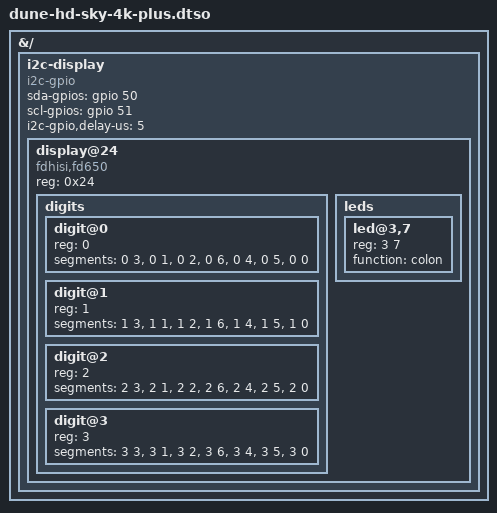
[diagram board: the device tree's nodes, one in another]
/dts-v1/;
/plugin/;

#include <dt-bindings/gpio/gpio.h>
#include <dt-bindings/leds/common.h>

&{/} {

	i2c-display {
		compatible = "i2c-gpio";
		sda-gpios = <&gpio 50 (GPIO_ACTIVE_HIGH | GPIO_OPEN_DRAIN)>;
		scl-gpios = <&gpio 51 (GPIO_ACTIVE_HIGH | GPIO_OPEN_DRAIN)>;
		i2c-gpio,delay-us = <5>;
		#address-cells = <1>;
		#size-cells = <0>;

		display@24 {
			compatible = "fdhisi,fd650", "titanmec,tm1650";
			reg = <0x24>;

			digits {
				#address-cells = <1>;
				#size-cells = <0>;
				digit@0 {
					reg = <0>;
					segments = <0 3>,
						   <0 1>,
						   <0 2>,
						   <0 6>,
						   <0 4>,
						   <0 5>,
						   <0 0>;
				};
				digit@1 {
					reg = <1>;
					segments = <1 3>,
						   <1 1>,
						   <1 2>,
						   <1 6>,
						   <1 4>,
						   <1 5>,
						   <1 0>;
				};
				digit@2 {
					reg = <2>;
					segments = <2 3>,
						   <2 1>,
						   <2 2>,
						   <2 6>,
						   <2 4>,
						   <2 5>,
						   <2 0>;
				};
				digit@3 {
					reg = <3>;
					segments = <3 3>,
						   <3 1>,
						   <3 2>,
						   <3 6>,
						   <3 4>,
						   <3 5>,
						   <3 0>;
				};
			};

			leds {
				#address-cells = <2>;
				#size-cells = <0>;
				led@3,7 {
					reg = <3 7>;
					function = "colon";
				};
			};
		};
	};
};
